# TMS320F280049 register map
Vendor: Texas Instruments; Series: C2000 F28004x; File version: 0.2.0-generated
Registers are 16-bit, read-write, reset 0x0 unless marked. A register's access mark holds for its fields unless they carry their own. Offsets are from the block's base; [hi:lo] are bit positions; {n}, {i} and the like mark numbered series; 'fields as' and 'values as' point back to an identical list.

## CANAREGS — CAN Registers
Base 0x00090000
Same registers: CANBREGS 0x00094000
0x00 CAN_CTL 32-bit — CAN Control Register
  [20] DE3 — Enable DMA request line
  [19] DE2 — Enable DMA request line
  [18] DE1 — Enable DMA request line
  [17] IE1 — Interrupt line 1 Enable Disabled
  [16] INITDBG — Debug Mode Status
  [15] SWR — SW Reset Enable
  [16:13] PMD — Parity on/off
  [9] ABO — Auto-Bus-On Enable
  [8] IDS — Interruption Debug Support Enable
  [7] TEST — Test Mode Enable
  [6] CCE — Configuration Change Enable
  [5] DAR — Disable Automatic Retransmission
  [3] EIE — Error Interrupt Enable
  [2] SIE — Status Change Interrupt Enable
  [1] IE0 — Interrupt line 0 Enable
  [0] INIT — Initialization
0x08 CAN_ES 32-bit — Error and Status Register
  [8] PER — Parity Error Detected
  [7] BOFF — Bus-Off State
  [6] EWARN — Warning State
  [5] EPASS — Error Passive State
  [4] RXOK — Reception status
  [3] TXOK — Transmission status
  [4:2] LEC — Last Error Code
0x10 CAN_ERRC 32-bit — Error Counter Register
  [15] RP — Receive Error Passive
  [20:14] REC — Receive Error Counter
  [14:7] TEC — Transmit Error Counter
0x18 CAN_BTR 32-bit — Bit Timing Register
  [22:19] BRPE — Baud Rate Prescaler Extension
  [16:14] TSEG2 — Time segment
  [14:11] TSEG1 — Time segment
  [8:7] SJW — Synchronization Jump Width
  [10:5] BRP — Baud Rate Prescaler
0x20 CAN_INT 32-bit — Interrupt Register
  [30:23] INT1ID — Interrupt 1 Identifier
  [30:15] INT0ID — Interrupt Identifier
0x28 CAN_TEST 32-bit — Test Register
  [9] RDA — RAM Direct Access Enable:
  [8] EXL — External Loopback Mode
  [7] RX — CANRX Pin Status
  [7:6] TX — CANTX Pin Control
  [4] LBACK — Loopback Mode
  [3] SILENT — Silent Mode
0x38 CAN_PERR 32-bit — CAN Parity Error Code Register
  [12:10] WORD_NUM — Word Number
  [14:7] MSG_NUM — Message Number
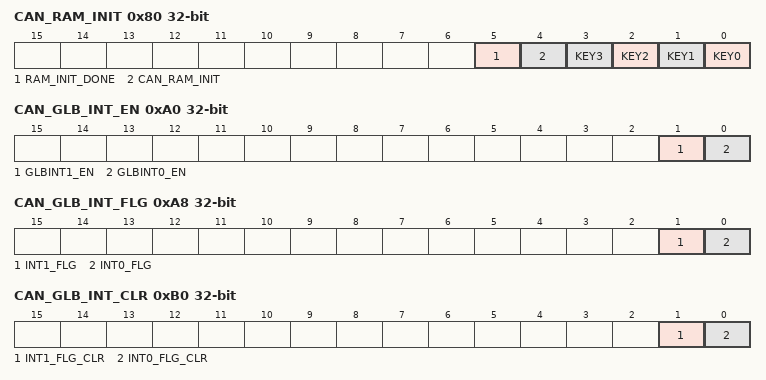
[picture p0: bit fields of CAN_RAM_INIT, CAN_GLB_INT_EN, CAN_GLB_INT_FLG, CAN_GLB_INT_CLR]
0x80 CAN_RAM_INIT 32-bit — CAN RAM Initialization Register
  [5] RAM_INIT_DONE — CAN RAM initialization complete
  [4] CAN_RAM_INIT — Initialize CAN Mailbox RAM
  [n] KEY{n} (n=0..3)
0xA0 CAN_GLB_INT_EN 32-bit — CAN Global Interrupt Enable Register
  [1] GLBINT1_EN — Global Interrupt Enable for CANINT1
  [0] GLBINT0_EN — Global Interrupt Enable for CANINT0
0xA8 CAN_GLB_INT_FLG 32-bit — CAN Global Interrupt Flag Register
  [1] INT1_FLG — Global Interrupt Flag for CANINT1
  [0] INT0_FLG — Global Interrupt Flag for CANINT0
0xB0 CAN_GLB_INT_CLR 32-bit — CAN Global Interrupt Clear Register
  [1] INT1_FLG_CLR — Global Interrupt flag clear for CANINT1
  [0] INT0_FLG_CLR — Global Interrupt flag clear for CANINT0
0x100 CAN_ABOTR 32-bit — Auto-Bus-On Time Register
  [31] ABO_TIME — Auto-Bus-On Timer
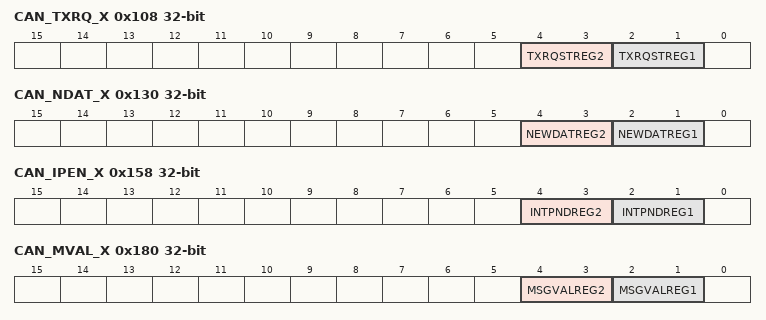
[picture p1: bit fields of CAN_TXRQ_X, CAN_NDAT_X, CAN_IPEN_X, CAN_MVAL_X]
0x108 CAN_TXRQ_X 32-bit — CAN Transmission Request Register
  [4:3] TXRQSTREG2 — Transmit Request Register 2
  [2:1] TXRQSTREG1 — Transmit Request Register 1
0x110 CAN_TXRQ_21 32-bit — CAN Transmission Request 2_1 Register
  [31] TXRQST — Transmission Request Bits
0x130 CAN_NDAT_X 32-bit — CAN New Data Register
  [4:3] NEWDATREG2 — New Data Register 2
  [2:1] NEWDATREG1 — New Data Register 1
0x138 CAN_NDAT_21 32-bit — CAN New Data 2_1 Register
  [31] NEWDAT — New Data Bits
0x158 CAN_IPEN_X 32-bit — CAN Interrupt Pending Register
  [4:3] INTPNDREG2 — Interrupt Pending Register 2
  [2:1] INTPNDREG1 — Interrupt Pending Register 1
0x160 CAN_IPEN_21 32-bit — CAN Interrupt Pending 2_1 Register
  [31] INTPND — Interrupt Pending
0x180 CAN_MVAL_X 32-bit — CAN Message Valid Register
  [4:3] MSGVALREG2 — Message Valid Register 2
  [2:1] MSGVALREG1 — Message Valid Register 1
0x188 CAN_MVAL_21 32-bit — CAN Message Valid 2_1 Register
  [31] MSGVALREG — Message Valid Bits
0x1B0 CAN_IP_MUX21 32-bit — CAN Interrupt Multiplexer 2_1 Register
  [31] INTMUX — Interrupt Mux
0x200 CAN_IF1CMD 32-bit — IF1 Command Register
  [23] DIR — Write/Read Direction
  [22] MASK — Access Mask Bits
  [21] ARB — Access Arbitration Bits
  [20] CONTROL — Access Control Bits
  [19] CLRINTPND — Clear Interrupt Pending Bit
  [18] TXRQST — Access Transmission Request Bit
  [17] DATA_A — Access Data Bytes 0-3
  [16] DATA_B — Access Data Bytes 4-7
  [15] BUSY — Busy Flag
  [14] DMAACTIVE — DMA Status
  [14:7] MSG_NUM — Message Number
0x208 CAN_IF1MSK 32-bit — IF1 Mask Register
  [31] MXTD — Mask Extended Identifier
  [30] MDIR — Mask Message Direction
  [31:28] MSK — Identifier Mask
0x210 CAN_IF1ARB 32-bit — IF1 Arbitration Register
  [31] MSGVAL — Message Valid
  [30] XTD — Extended Identifier
  [29] DIR — Message Direction
  [31:28] ID — `
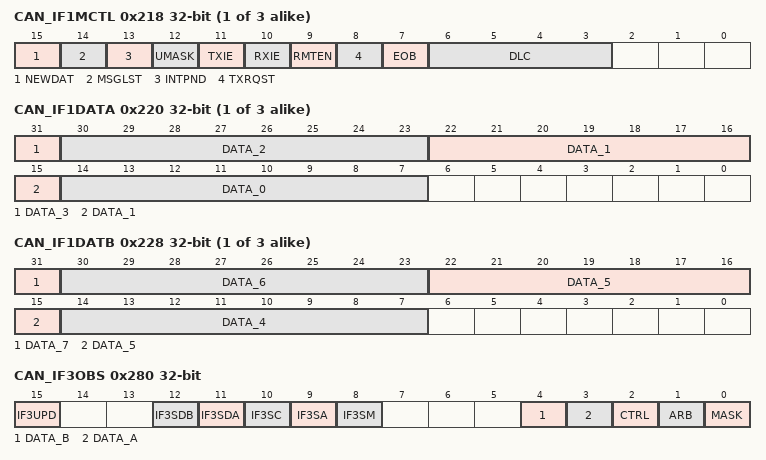
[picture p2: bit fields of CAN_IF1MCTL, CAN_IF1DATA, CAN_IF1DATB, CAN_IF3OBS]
{0x1D8+0x40*i} CAN_IF{i}MCTL 32-bit (i=1..3) — IF{i} Message Control Register
  [15] NEWDAT — New Data
  [14] MSGLST — Message Lost
  [13] INTPND — Interrupt Pending
  [12] UMASK — Use Acceptance Mask
  [11] TXIE — Transmit Interrupt Enable
  [10] RXIE — Receive Interrupt Enable
  [9] RMTEN — Remote Enable
  [8] TXRQST — Transmit Request
  [7] EOB — End of Block
  [6:3] DLC — Data length code
{0x1E0+0x40*i} CAN_IF{i}DATA 32-bit (i=1..3) — IF{i} Data A Register
  [31] DATA_3 — Data Byte 3
  [30:23] DATA_2 — Data Byte 2
  [22:15] DATA_1 — Data Byte 1
  [14:7] DATA_0 — Data Byte 0
{0x1E8+0x40*i} CAN_IF{i}DATB 32-bit (i=1..3) — IF{i} Data B Register
  [31] DATA_7 — Data Byte 7
  [30:23] DATA_6 — Data Byte 6
  [22:15] DATA_5 — Data Byte 5
  [14:7] DATA_4 — Data Byte 4
0x240 CAN_IF2CMD 32-bit — IF2 Command Register
  fields as CAN_IF1CMD
0x248 CAN_IF2MSK 32-bit — IF2 Mask Register
  fields as CAN_IF1MSK
0x250 CAN_IF2ARB 32-bit — IF2 Arbitration Register
  [31] MSGVAL — Message Valid
  [30] XTD — Extended Identifier
  [29] DIR — Message Direction
  [31:28] ID — Message Identifier
0x280 CAN_IF3OBS 32-bit — IF3 Observation Register
  [15] IF3UPD — IF3 Update Data
  [12] IF3SDB — IF3 Status of Data B read access
  [11] IF3SDA — IF3 Status of Data A read access
  [10] IF3SC — IF3 Status of Control bits read access
  [9] IF3SA — IF3 Status of Arbitration data read access
  [8] IF3SM — IF3 Status of Mask data read access
  [4] DATA_B — Data B read observation
  [3] DATA_A — Data A read observation
  [2] CTRL — Ctrl read observation
  [1] ARB — Arbitration data read observation
  [0] MASK — Mask data read observation
0x288 CAN_IF3MSK 32-bit — IF3 Mask Register
  [31] MXTD — Mask Extended Identifier
  [30] MDIR — Mask Message Direction
  [31:28] MSK — Mask
0x290 CAN_IF3ARB 32-bit — IF3 Arbitration Register
  fields as CAN_IF2ARB
0x2C0 CAN_IF3UPD 32-bit — IF3 Update Enable Register
  [31] IF3UPDEN — IF3 Update Enabled
